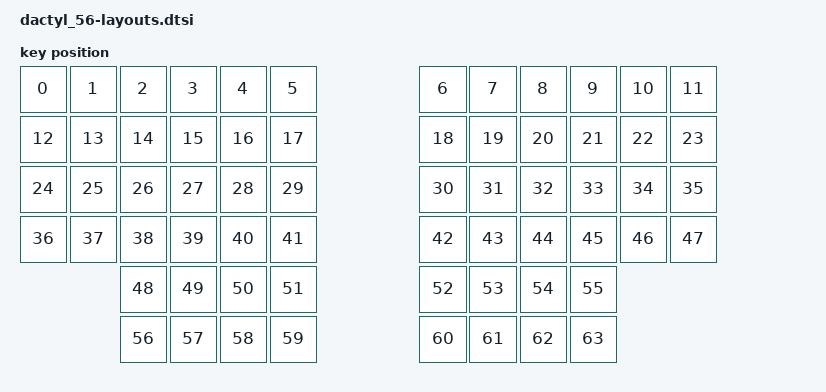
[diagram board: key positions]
/// Generated using ./dactyl_56.json
/// Edit the json using https://nickcoutsos.github.io/keymap-layout-tools/
/// Convert it to dtsi using: https://zmk-physical-layout-converter.streamlit.app/

#include <physical_layouts.dtsi>

/ {
    physical_layout0: physical_layout_0 {
        compatible = "zmk,physical-layout";
        display-name = "default_layout";

        transform = <&default_transform>;
        kscan = <&kscan0>;

        keys  //                     w   h    x    y     rot    rx    ry
            = <&key_physical_attrs 100 100    0    0       0     0     0>
            , <&key_physical_attrs 100 100  100    0       0     0     0>
            , <&key_physical_attrs 100 100  200    0       0     0     0>
            , <&key_physical_attrs 100 100  300    0       0     0     0>
            , <&key_physical_attrs 100 100  400    0       0     0     0>
            , <&key_physical_attrs 100 100  500    0       0     0     0>
            , <&key_physical_attrs 100 100  800    0       0     0     0>
            , <&key_physical_attrs 100 100  900    0       0     0     0>
            , <&key_physical_attrs 100 100 1000    0       0     0     0>
            , <&key_physical_attrs 100 100 1100    0       0     0     0>
            , <&key_physical_attrs 100 100 1200    0       0     0     0>
            , <&key_physical_attrs 100 100 1300    0       0     0     0>
            , <&key_physical_attrs 100 100    0  100       0     0     0>
            , <&key_physical_attrs 100 100  100  100       0     0     0>
            , <&key_physical_attrs 100 100  200  100       0     0     0>
            , <&key_physical_attrs 100 100  300  100       0     0     0>
            , <&key_physical_attrs 100 100  400  100       0     0     0>
            , <&key_physical_attrs 100 100  500  100       0     0     0>
            , <&key_physical_attrs 100 100  800  100       0     0     0>
            , <&key_physical_attrs 100 100  900  100       0     0     0>
            , <&key_physical_attrs 100 100 1000  100       0     0     0>
            , <&key_physical_attrs 100 100 1100  100       0     0     0>
            , <&key_physical_attrs 100 100 1200  100       0     0     0>
            , <&key_physical_attrs 100 100 1300  100       0     0     0>
            , <&key_physical_attrs 100 100    0  200       0     0     0>
            , <&key_physical_attrs 100 100  100  200       0     0     0>
            , <&key_physical_attrs 100 100  200  200       0     0     0>
            , <&key_physical_attrs 100 100  300  200       0     0     0>
            , <&key_physical_attrs 100 100  400  200       0     0     0>
            , <&key_physical_attrs 100 100  500  200       0     0     0>
            , <&key_physical_attrs 100 100  800  200       0     0     0>
            , <&key_physical_attrs 100 100  900  200       0     0     0>
            , <&key_physical_attrs 100 100 1000  200       0     0     0>
            , <&key_physical_attrs 100 100 1100  200       0     0     0>
            , <&key_physical_attrs 100 100 1200  200       0     0     0>
            , <&key_physical_attrs 100 100 1300  200       0     0     0>
            , <&key_physical_attrs 100 100    0  300       0     0     0>
            , <&key_physical_attrs 100 100  100  300       0     0     0>
            , <&key_physical_attrs 100 100  200  300       0     0     0>
            , <&key_physical_attrs 100 100  300  300       0     0     0>
            , <&key_physical_attrs 100 100  400  300       0     0     0>
            , <&key_physical_attrs 100 100  500  300       0     0     0>
            , <&key_physical_attrs 100 100  800  300       0     0     0>
            , <&key_physical_attrs 100 100  900  300       0     0     0>
            , <&key_physical_attrs 100 100 1000  300       0     0     0>
            , <&key_physical_attrs 100 100 1100  300       0     0     0>
            , <&key_physical_attrs 100 100 1200  300       0     0     0>
            , <&key_physical_attrs 100 100 1300  300       0     0     0>
            , <&key_physical_attrs 100 100  200  400       0     0     0>
            , <&key_physical_attrs 100 100  300  400       0     0     0>
            , <&key_physical_attrs 100 100  400  400       0     0     0>
            , <&key_physical_attrs 100 100  500  400       0     0     0>
            , <&key_physical_attrs 100 100  800  400       0     0     0>
            , <&key_physical_attrs 100 100  900  400       0     0     0>
            , <&key_physical_attrs 100 100 1000  400       0     0     0>
            , <&key_physical_attrs 100 100 1100  400       0     0     0>
            , <&key_physical_attrs 100 100  200  500       0     0     0>
            , <&key_physical_attrs 100 100  300  500       0     0     0>
            , <&key_physical_attrs 100 100  400  500       0     0     0>
            , <&key_physical_attrs 100 100  500  500       0     0     0>
            , <&key_physical_attrs 100 100  800  500       0     0     0>
            , <&key_physical_attrs 100 100  900  500       0     0     0>
            , <&key_physical_attrs 100 100 1000  500       0     0     0>
            , <&key_physical_attrs 100 100 1100  500       0     0     0>
            ;
    };
};
